# TPCC register map
Vendor: Texas Instruments
Registers are 32-bit, read-only, no defined reset value unless marked. A register's access mark holds for its fields unless they carry their own. Offsets are as the file gives them; [hi:lo] are bit positions; {n}, {i} and the like mark numbered series.

## TPCC (part 2 of 2)
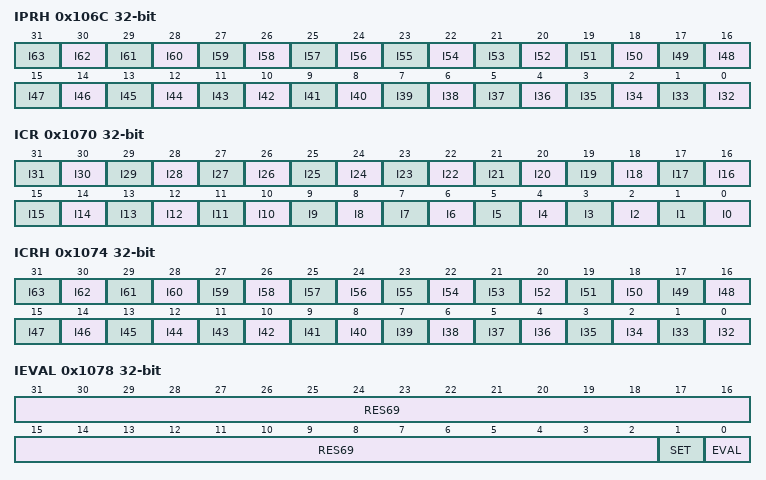
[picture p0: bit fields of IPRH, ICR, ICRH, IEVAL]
0x106C IPRH — Interrupt Pending Register (High Part): IPRH.In bit is set when a interrupt completion code with TCC of N is detected. IPRH.In bit is cleared via software by writing a '1' to ICRH.In bit.
  [n-32] I{n} (n=32..63) — Interrupt associated with TCC #{n}
0x1070 ICR wo — Interrupt Clear Register: CPU write of '1' to the ICR.In bit causes the IPR.In bit to be cleared. CPU write of '0' has no effect. All IPR.In bits must be cleared before additional interrupts will be asserted by CC.
  [n] I{n} (n=0..31) — Interrupt associated with TCC #{n}
0x1074 ICRH wo — Interrupt Clear Register (High Part): CPU write of '1' to the ICRH.In bit causes the IPRH.In bit to be cleared. CPU write of '0' has no effect. All IPRH.In bits must be cleared before additional interrupts will be asserted by CC.
  [n-32] I{n} (n=32..63) — Interrupt associated with TCC #{n}
0x1078 IEVAL access per field — Interrupt Eval Register
  [31:2] RES69 ro — RESERVE FIELD
  [1] SET wo — Interrupt Set: CPU write of '1' to the SETn bit causes the tpcc_intN output signal to be pulsed egardless of state of interrupts enable (IERn) and status (IPRn). CPU write of '0' has no effect.
  [0] EVAL wo — Interrupt Evaluate: CPU write of '1' to the EVALn bit causes the tpcc_intN output signal to be pulsed if any enabled interrupts (IERn) are still pending (IPRn). CPU write of '0' has no effect..
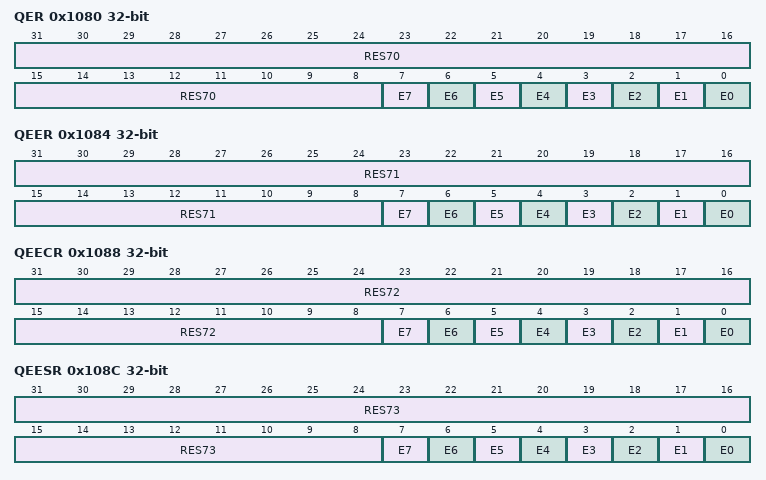
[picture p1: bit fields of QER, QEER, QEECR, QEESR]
0x1080 QER — QDMA Event Register: If QER.En bit is set then the corresponding QDMA channel is prioritized vs. other qdma events for submission to the TC. QER.En bit is set when a vbus write byte matches the address defined in the QCHMAPn register. QER.En bit is cleared when the corresponding event is prioritized and serviced. QER.En is also cleared when user writes a '1' to the QSECR.En bit. If the QER.En bit is already set and a new QDMA event is detected due to user write to QDMA trigger location and QEER register is set then the corresponding bit in the QDMA Event Missed Register is set.
  [31:8] RES70 — RESERVE FIELD
  [n] E{n} (n=0..7) — Event #{n}
0x1084 QEER — QDMA Event Enable Register: Enabled/disabled QDMA address comparator for QDMA Channel N. QEER.En is not directly writeable. QDMA channels can be enabled via writes to QEESR and can be disabled via writes to QEECR register. QEER.En = 1 The corresponding QDMA channel comparator is enabled and Events will be recognized and latched in QER.En. QEER.En = 0 The corresponding QDMA channel comparator is disabled. Events will not be recognized/latched in QER.En.
  [31:8] RES71 — RESERVE FIELD
  [n] E{n} (n=0..7) — Event #{n}
0x1088 QEECR access per field — QDMA Event Enable Clear Register: CPU write of '1' to the QEECR.En bit causes the QEER.En bit to be cleared. CPU write of '0' has no effect..
  [31:8] RES72 ro — RESERVE FIELD
  [n] E{n} wo (n=0..7) — Event #{n}
0x108C QEESR access per field — QDMA Event Enable Set Register: CPU write of '1' to the QEESR.En bit causes the QEESR.En bit to be set. CPU write of '0' has no effect..
  [31:8] RES73 ro — RESERVE FIELD
  [n] E{n} wo (n=0..7) — Event #{n}
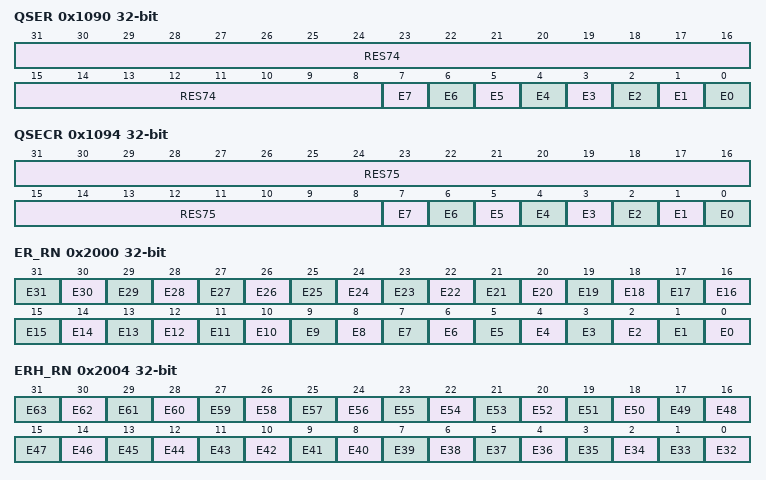
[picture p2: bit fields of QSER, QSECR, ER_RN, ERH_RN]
0x1090 QSER — QDMA Secondary Event Register: The QDMA secondary event register is used along with the QDMA Event Register (QER) to provide information on the state of a QDMA Event. En = 0 : Event is not currently in the Event Queue. En = 1 : Event is currently stored in Event Queue. Event arbiter will not prioritize additional events.
  [31:8] RES74 — RESERVE FIELD
  [n] E{n} (n=0..7) — Event #{n}
0x1094 QSECR access per field — QDMA Secondary Event Clear Register: The secondary event clear register is used to clear the status of the QSER and QER register (note that this is slightly different than the SER operation which does not clear the ER.En register). CPU write of '1' to the QSECR.En bit clears the QSER.En and QER.En register fields. CPU write of '0' has no effect..
  [31:8] RES75 ro — RESERVE FIELD
  [n] E{n} wo (n=0..7) — Event #{n}
0x2000 ER_RN — Event Register: If ER.En bit is set and the EER.En bit is also set then the corresponding DMA channel is prioritized vs. other pending DMA events for submission to the TC. ER.En bit is set when the input event #n transitions from inactive (low) to active (high) regardless of the state of EER.En bit. ER.En bit is cleared when the corresponding event is prioritized and serviced. If the ER.En bit is already set and a new inactive to active transition is detected on the input event #n input AND the corresponding bit in the EER register is set then the corresponding bit in the Event Missed Register is set. Event N can be cleared via sw by writing a '1' to the ECR pseudo-register.
  [n] E{n} (n=0..31) — Event #{n}
0x2004 ERH_RN — Event Register (High Part): If ERH.En bit is set and the EERH.En bit is also set then the corresponding DMA channel is prioritized vs. other pending DMA events for submission to the TC. ERH.En bit is set when the input event #n transitions from inactive (low) to active (high) regardless of the state of EERH.En bit. ER.En bit is cleared when the corresponding event is prioritized and serviced. If the ERH.En bit is already set and a new inactive to active transition is detected on the input event #n input AND the corresponding bit in the EERH register is set then the corresponding bit in the Event Missed Register is set. Event N can be cleared via sw by writing a '1' to the ECRH pseudo-register.
  [n-32] E{n} (n=32..63) — Event #{n}
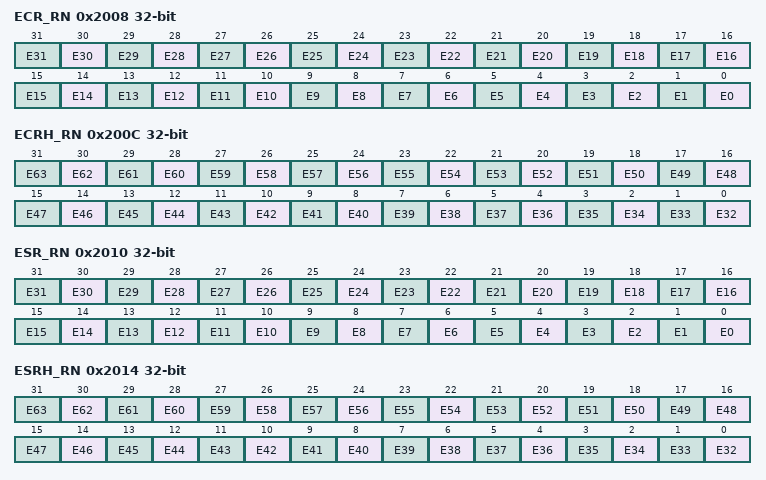
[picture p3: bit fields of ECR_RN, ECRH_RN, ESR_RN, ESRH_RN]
0x2008 ECR_RN wo — Event Clear Register: CPU write of '1' to the ECR.En bit causes the ER.En bit to be cleared. CPU write of '0' has no effect.
  [n] E{n} (n=0..31) — Event #{n}
0x200C ECRH_RN wo — Event Clear Register (High Part): CPU write of '1' to the ECRH.En bit causes the ERH.En bit to be cleared. CPU write of '0' has no effect.
  [n-32] E{n} (n=32..63) — Event #{n}
0x2010 ESR_RN wo — Event Set Register: CPU write of '1' to the ESR.En bit causes the ER.En bit to be set. CPU write of '0' has no effect.
  [n] E{n} (n=0..31) — Event #{n}
0x2014 ESRH_RN wo — Event Set Register (High Part) CPU write of '1' to the ESRH.En bit causes the ERH.En bit to be set. CPU write of '0' has no effect.
  [n-32] E{n} (n=32..63) — Event #{n}
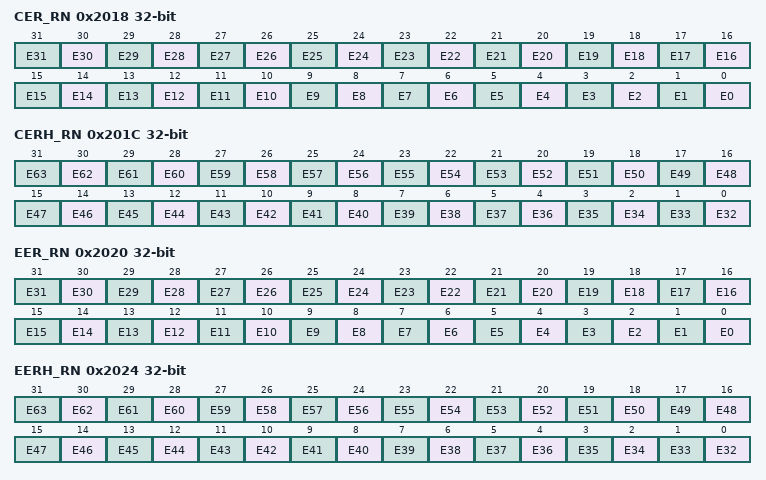
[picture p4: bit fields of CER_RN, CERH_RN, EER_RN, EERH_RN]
0x2018 CER_RN — Chained Event Register: If CER.En bit is set (regardless of state of EER.En) then the corresponding DMA channel is prioritized vs. other pending DMA events for submission to the TC. CER.En bit is set when a chaining completion code is returned from one of the 3PTCs via the completion interface or is generated internally via Early Completion path. CER.En bit is cleared when the corresponding event is prioritized and serviced. If the CER.En bit is already set and the corresponding chaining completion code is returned from the TC then the corresponding bit in the Event Missed Register is set. CER.En cannot be set or cleared via software.
  [n] E{n} (n=0..31) — Event #{n}
0x201C CERH_RN — Chained Event Register (High Part): If CERH.En bit is set (regardless of state of EERH.En) then the corresponding DMA channel is prioritized vs. other pending DMA events for submission to the TC. CERH.En bit is set when a chaining completion code is returned from one of the 3PTCs via the completion interface or is generated internally via Early Completion path. CERH.En bit is cleared when the corresponding event is prioritized and serviced. If the CERH.En bit is already set and the corresponding chaining completion code is returned from the TC then the corresponding bit in the Event Missed Register is set. CERH.En cannot be set or cleared via software.
  [n-32] E{n} (n=32..63) — Event #{n}
0x2020 EER_RN — Event Enable Register: Enables DMA transfers for ER.En pending events. ER.En is set based on externally asserted events (via tpcc_eventN_pi). This register has no effect on Chained Event Register (CER) or Event Set Register (ESR). Note that if a bit is set in ER.En while EER.En is disabled no action is taken. If EER.En is enabled at a later point (and ER.En has not been cleared via SW) then the event will be recognized as a valid 'TR Sync' EER.En is not directly writeable. Events can be enabled via writes to EESR and can be disabled via writes to EECR register. EER.En = 0: ER.En is not enabled to trigger DMA transfers. EER.En = 1: ER.En is enabled to trigger DMA transfers.
  [n] E{n} (n=0..31) — Event #{n}
0x2024 EERH_RN — Event Enable Register (High Part): Enables DMA transfers for ERH.En pending events. ERH.En is set based on externally asserted events (via tpcc_eventN_pi). This register has no effect on Chained Event Register (CERH) or Event Set Register (ESRH). Note that if a bit is set in ERH.En while EERH.En is disabled no action is taken. If EERH.En is enabled at a later point (and ERH.En has not been cleared via SW) then the event will be recognized as a valid 'TR Sync' EERH.En is not directly writeable. Events can be enabled via writes to EESRH and can be disabled via writes to EECRH register. EERH.En = 0: ER.En is not enabled to trigger DMA transfers. EERH.En = 1: ER.En is enabled to trigger DMA transfers.
  [n-32] E{n} (n=32..63) — Event #{n}
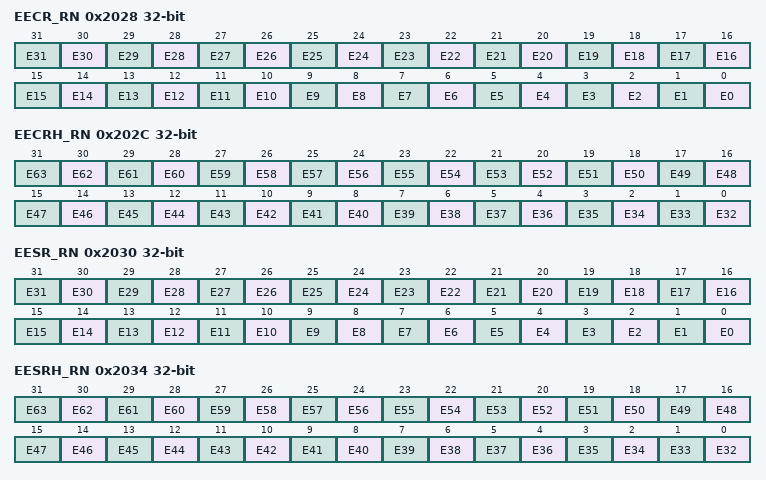
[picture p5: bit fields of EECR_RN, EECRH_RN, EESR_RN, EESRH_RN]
0x2028 EECR_RN wo — Event Enable Clear Register: CPU write of '1' to the EECR.En bit causes the EER.En bit to be cleared. CPU write of '0' has no effect..
  [n] E{n} (n=0..31) — Event #{n}
0x202C EECRH_RN wo — Event Enable Clear Register (High Part): CPU write of '1' to the EECRH.En bit causes the EERH.En bit to be cleared. CPU write of '0' has no effect..
  [n-32] E{n} (n=32..63) — Event #{n}
0x2030 EESR_RN wo — Event Enable Set Register: CPU write of '1' to the EESR.En bit causes the EER.En bit to be set. CPU write of '0' has no effect..
  [n] E{n} (n=0..31) — Event #{n}
0x2034 EESRH_RN wo — Event Enable Set Register (High Part): CPU write of '1' to the EESRH.En bit causes the EERH.En bit to be set. CPU write of '0' has no effect..
  [n-32] E{n} (n=32..63) — Event #{n}
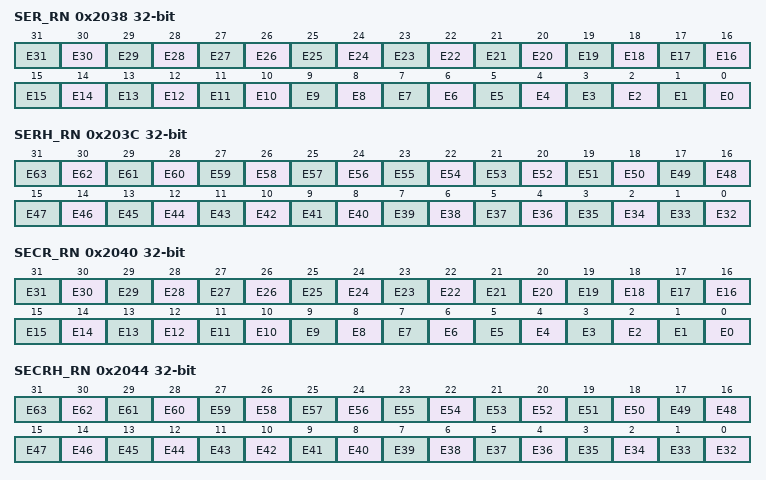
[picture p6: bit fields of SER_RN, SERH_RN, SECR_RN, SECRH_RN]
0x2038 SER_RN — Secondary Event Register: The secondary event register is used along with the Event Register (ER) to provide information on the state of an Event. En = 0 : Event is not currently in the Event Queue. En = 1 : Event is currently stored in Event Queue. Event arbiter will not prioritize additional events.
  [n] E{n} (n=0..31) — Event #{n}
0x203C SERH_RN — Secondary Event Register (High Part): The secondary event register is used along with the Event Register (ERH) to provide information on the state of an Event. En = 0 : Event is not currently in the Event Queue. En = 1 : Event is currently stored in Event Queue. Event arbiter will not prioritize additional events.
  [n-32] E{n} (n=32..63) — Event #{n}
0x2040 SECR_RN wo — Secondary Event Clear Register: The secondary event clear register is used to clear the status of the SER registers. CPU write of '1' to the SECR.En bit clears the SER register. CPU write of '0' has no effect.
  [n] E{n} (n=0..31) — Event #{n}
0x2044 SECRH_RN wo — Secondary Event Clear Register (High Part): The secondary event clear register is used to clear the status of the SERH registers. CPU write of '1' to the SECRH.En bit clears the SERH register. CPU write of '0' has no effect.
  [n-32] E{n} (n=32..63) — Event #{n}
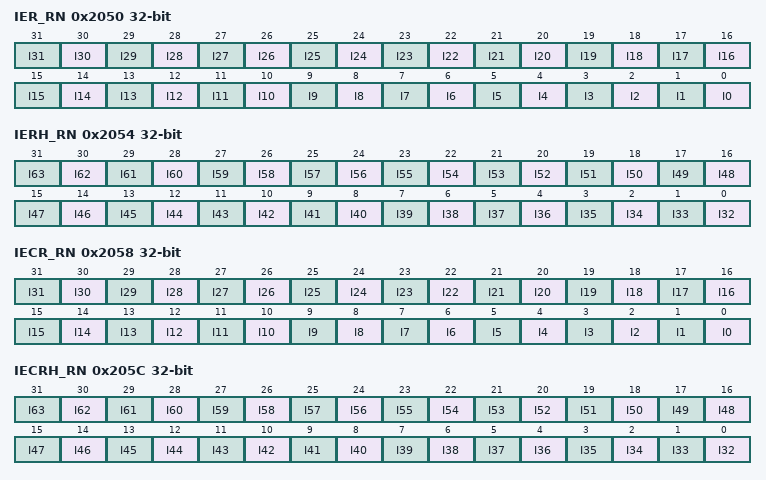
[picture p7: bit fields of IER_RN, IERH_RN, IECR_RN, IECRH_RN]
0x2050 IER_RN — Int Enable Register: IER.In is not directly writeable. Interrupts can be enabled via writes to IESR and can be disabled via writes to IECR register. IER.In = 0: IPR.In is NOT enabled for interrupts. IER.In = 1: IPR.In IS enabled for interrupts.
  [n] I{n} (n=0..31) — Interrupt associated with TCC #{n}
0x2054 IERH_RN — Int Enable Register (High Part): IERH.In is not directly writeable. Interrupts can be enabled via writes to IESRH and can be disabled via writes to IECRH register. IERH.In = 0: IPRH.In is NOT enabled for interrupts. IERH.In = 1: IPRH.In IS enabled for interrupts.
  [n-32] I{n} (n=32..63) — Interrupt associated with TCC #{n}
0x2058 IECR_RN wo — Int Enable Clear Register: CPU write of '1' to the IECR.In bit causes the IER.In bit to be cleared. CPU write of '0' has no effect..
  [n] I{n} (n=0..31) — Interrupt associated with TCC #{n}
0x205C IECRH_RN wo — Int Enable Clear Register (High Part): CPU write of '1' to the IECRH.In bit causes the IERH.In bit to be cleared. CPU write of '0' has no effect..
  [n-32] I{n} (n=32..63) — Interrupt associated with TCC #{n}
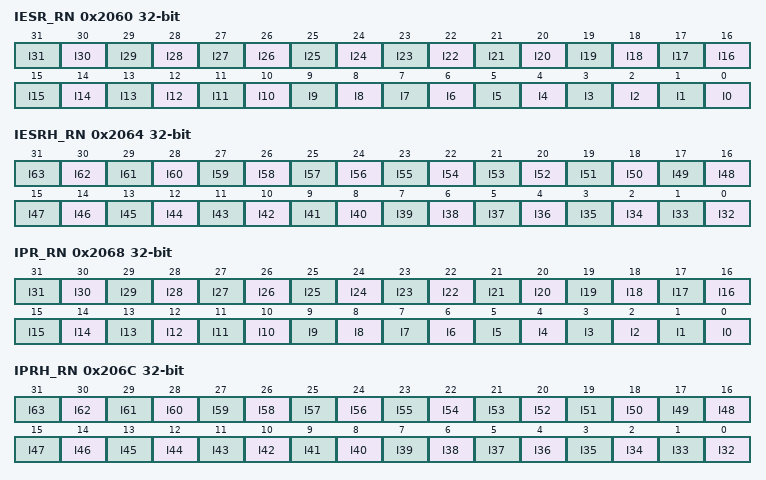
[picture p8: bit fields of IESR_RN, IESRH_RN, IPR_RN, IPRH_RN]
0x2060 IESR_RN wo — Int Enable Set Register: CPU write of '1' to the IESR.In bit causes the IESR.In bit to be set. CPU write of '0' has no effect..
  [n] I{n} (n=0..31) — Interrupt associated with TCC #{n}
0x2064 IESRH_RN wo — Int Enable Set Register (High Part): CPU write of '1' to the IESRH.In bit causes the IESRH.In bit to be set. CPU write of '0' has no effect..
  [n-32] I{n} (n=32..63) — Interrupt associated with TCC #{n}
0x2068 IPR_RN — Interrupt Pending Register: IPR.In bit is set when a interrupt completion code with TCC of N is detected. IPR.In bit is cleared via software by writing a '1' to ICR.In bit.
  [n] I{n} (n=0..31) — Interrupt associated with TCC #{n}
0x206C IPRH_RN — Interrupt Pending Register (High Part): IPRH.In bit is set when a interrupt completion code with TCC of N is detected. IPRH.In bit is cleared via software by writing a '1' to ICRH.In bit.
  [n-32] I{n} (n=32..63) — Interrupt associated with TCC #{n}
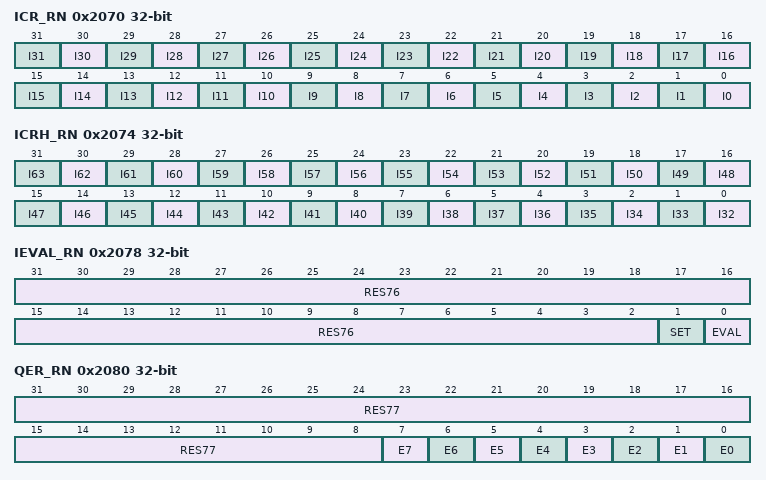
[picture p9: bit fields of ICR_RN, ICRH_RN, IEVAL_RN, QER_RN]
0x2070 ICR_RN wo — Interrupt Clear Register: CPU write of '1' to the ICR.In bit causes the IPR.In bit to be cleared. CPU write of '0' has no effect. All IPR.In bits must be cleared before additional interrupts will be asserted by CC.
  [n] I{n} (n=0..31) — Interrupt associated with TCC #{n}
0x2074 ICRH_RN wo — Interrupt Clear Register (High Part): CPU write of '1' to the ICRH.In bit causes the IPRH.In bit to be cleared. CPU write of '0' has no effect. All IPRH.In bits must be cleared before additional interrupts will be asserted by CC.
  [n-32] I{n} (n=32..63) — Interrupt associated with TCC #{n}
0x2078 IEVAL_RN access per field — Interrupt Eval Register
  [31:2] RES76 ro — RESERVE FIELD
  [1] SET wo — Interrupt Set: CPU write of '1' to the SETn bit causes the tpcc_intN output signal to be pulsed egardless of state of interrupts enable (IERn) and status (IPRn). CPU write of '0' has no effect.
  [0] EVAL wo — Interrupt Evaluate: CPU write of '1' to the EVALn bit causes the tpcc_intN output signal to be pulsed if any enabled interrupts (IERn) are still pending (IPRn). CPU write of '0' has no effect..
0x2080 QER_RN — QDMA Event Register: If QER.En bit is set then the corresponding QDMA channel is prioritized vs. other qdma events for submission to the TC. QER.En bit is set when a vbus write byte matches the address defined in the QCHMAPn register. QER.En bit is cleared when the corresponding event is prioritized and serviced. QER.En is also cleared when user writes a '1' to the QSECR.En bit. If the QER.En bit is already set and a new QDMA event is detected due to user write to QDMA trigger location and QEER register is set then the corresponding bit in the QDMA Event Missed Register is set.
  [31:8] RES77 — RESERVE FIELD
  [n] E{n} (n=0..7) — Event #{n}
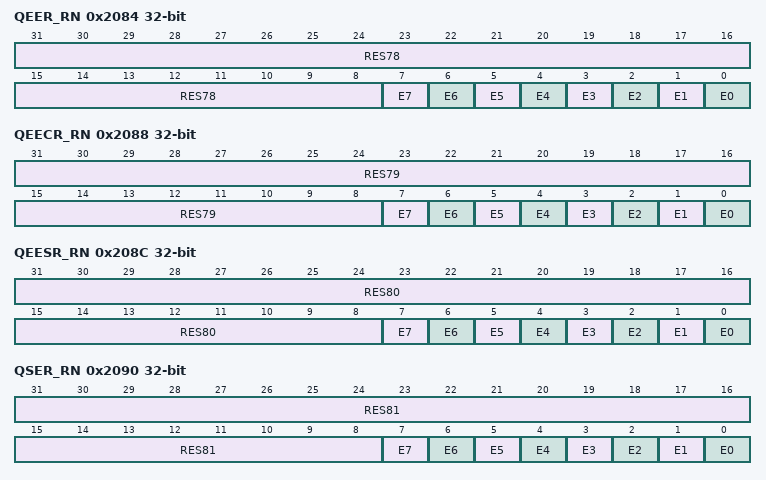
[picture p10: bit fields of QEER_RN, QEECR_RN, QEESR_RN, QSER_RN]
0x2084 QEER_RN — QDMA Event Enable Register: Enabled/disabled QDMA address comparator for QDMA Channel N. QEER.En is not directly writeable. QDMA channels can be enabled via writes to QEESR and can be disabled via writes to QEECR register. QEER.En = 1 The corresponding QDMA channel comparator is enabled and Events will be recognized and latched in QER.En. QEER.En = 0 The corresponding QDMA channel comparator is disabled. Events will not be recognized/latched in QER.En.
  [31:8] RES78 — RESERVE FIELD
  [n] E{n} (n=0..7) — Event #{n}
0x2088 QEECR_RN access per field — QDMA Event Enable Clear Register: CPU write of '1' to the QEECR.En bit causes the QEER.En bit to be cleared. CPU write of '0' has no effect..
  [31:8] RES79 ro — RESERVE FIELD
  [n] E{n} wo (n=0..7) — Event #{n}
0x208C QEESR_RN access per field — QDMA Event Enable Set Register: CPU write of '1' to the QEESR.En bit causes the QEESR.En bit to be set. CPU write of '0' has no effect..
  [31:8] RES80 ro — RESERVE FIELD
  [n] E{n} wo (n=0..7) — Event #{n}
0x2090 QSER_RN — QDMA Secondary Event Register: The QDMA secondary event register is used along with the QDMA Event Register (QER) to provide information on the state of a QDMA Event. En = 0 : Event is not currently in the Event Queue. En = 1 : Event is currently stored in Event Queue. Event arbiter will not prioritize additional events.
  [31:8] RES81 — RESERVE FIELD
  [n] E{n} (n=0..7) — Event #{n}
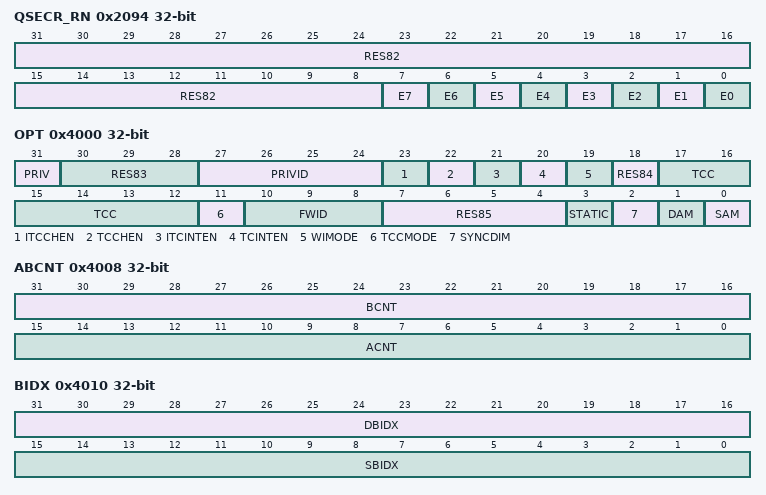
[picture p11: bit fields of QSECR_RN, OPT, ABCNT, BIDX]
0x2094 QSECR_RN access per field — QDMA Secondary Event Clear Register: The secondary event clear register is used to clear the status of the QSER and QER register (note that this is slightly different than the SER operation which does not clear the ER.En register). CPU write of '1' to the QSECR.En bit clears the QSER.En and QER.En register fields. CPU write of '0' has no effect..
  [31:8] RES82 ro — RESERVE FIELD
  [n] E{n} wo (n=0..7) — Event #{n}
0x4000 OPT access per field — Options Parameter
  [31] PRIV ro — Privilege level: privilege level (supervisor vs. user) for the host/cpu/dma that programmed this PaRAM Entry. Value is set with the vbus priv value when any part of the PaRAM Entry is written. Not writeable via vbus wdata bus. Is readable via VBus rdata bus. PRIV = 0 : User level privilege PRIV = 1 : Supervisor level privilege
  [30:28] RES83 ro — RESERVE FIELD
  [27:24] PRIVID ro — Privilege ID: Privilege ID for the external host/cpu/dma that programmed this PaRAM Entry. This value is set with the vbus privid value when any part of the PaRAM Entry is written. Not writeable via vbus wdata bus. Is readable via VBus rdata bus.
  [23] ITCCHEN rw — Intermediate transfer completion chaining enable: 0: Intermediate transfer complete chaining is disabled. 1: Intermediate transfer complete chaining is enabled.
  [22] TCCHEN rw — Transfer complete chaining enable: 0: Transfer complete chaining is disabled. 1: Transfer complete chaining is enabled.
  [21] ITCINTEN rw — Intermediate transfer completion interrupt enable: 0: Intermediate transfer complete interrupt is disabled. 1: Intermediate transfer complete interrupt is enabled (corresponding IER[TCC] bit must be set to 1 to generate interrupt)
  [20] TCINTEN rw — Transfer complete interrupt enable: 0: Transfer complete interrupt is disabled. 1: Transfer complete interrupt is enabled (corresponding IER[TCC] bit must be set to 1 to generate interrupt)
  [19] WIMODE rw — Backward compatibility mode: 0: Normal operation 1 : WI Backwards Compatibility mode forces BCNT to be adjusted by '1' upon TR submission (0 means 1 1 means 2 ... ) and forces ACNT to be treated as a word-count (left shifted by 2 by hardware to create byte cnt for TR submission)
  [18] RES84 ro — RESERVE FIELD
  [17:12] TCC rw — Transfer Complete Code: The 6-bit code is used to set the relevant bit in CER (bit CER[TCC]) for chaining or in IER (bit IER[TCC]) for interrupts.
  [11] TCCMODE rw — Transfer complete code mode: Indicates the point at which a transfer is considered completed. Applies to both chaining and interrupt. 0: Normal Completion A transfer is considered completed after the transfer parameters are returned to the CC from the TC (which was returned from the peripheral). 1: Early Completion A transfer is considered completed after the CC submits a TR to the TC. CC generates completion code internally .
  [10:8] FWID rw — FIFO width: Applies if either SAM or DAM is set to FIFO mode. Pass-thru to TC.
  [7:4] RES85 ro — RESERVE FIELD
  [3] STATIC rw — Static Entry: 0: Entry is updated as normal 1: Entry is static Count and Address updates are not updated after TRP is submitted. Linking is not performed.
  [2] SYNCDIM rw — Transfer Synchronization Dimension: 0: A-Sync Each event triggers the transfer of ACNT elements. 1: AB-Sync Each event triggers the transfer of BCNT arrays of ACNT elements
  [1] DAM rw — Destination Address Mode: Destination Address Mode within an array. Pass-thru to TC. 0: INCR Dst addressing within an array increments. Dst is not a FIFO. 1: FIFO Dst addressing within an array wraps around upon reaching FIFO width.
  [0] SAM rw — Source Address Mode: Source Address Mode within an array. Pass-thru to TC. 0: INCR Src addressing within an array increments. Source is not a FIFO. 1: FIFO Src addressing within an array wraps around upon reaching FIFO width.
0x4004 SRC rw — Source Address
  [31:0] SRC — Source Address: The 32-bit source address parameters specify the starting byte address of the source . If SAM is set to FIFO mode then the user should program the Source address to be aligned to the value specified by the OPT.FWID field. No errors are recognized here but TC will assert error if this is not true.
0x4008 ABCNT rw — A and B byte count
  [31:16] BCNT — BCNT : Count for 2nd Dimension: BCNT is a 16-bit unsigned value that specifies the number of arrays of length ACNT. For normal operation valid values for BCNT can be anywhere between 1 and 65535. Therefore the maximum number of arrays in a frame is 65535 (64K-1 arrays). BCNT=1 means 1 array in the frame and BCNT=0 means 0 arrays in the frame. In normal mode a BCNT of '0' is considered as either a Null or Dummy transfer. A Dummy or Null transfer will generate a Completion code depending on the settings of the completion bit fields of the OPT field. If the OPT.WIMODE bit is set then the programmed BCNT value will be incremented by '1' before submission to TC. I.e. 0 means 1 1 means 2 2 means 3 ...
  [15:0] ACNT — ACNT : number of bytes in 1st dimension: ACNT represents the number of bytes within the first dimension of a transfer. ACNT is a 16-bit unsigned value with valid values between 0 and 65535. Therefore the maximum number of bytes in an array is 65535 bytes (64K-1 bytes). ACNT must be greater than or equal to '1' for a TR to be submitted to TC. An ACNT of '0' is considered as either a null or dummy transfer. A Dummy or Null transfer will generate a Completion code depending on the settings of the completion bit fields of the OPT field. If the OPT.WIMODE bit is set then the ACNT field represents a word count. The CC must internally multiply by 4 to translate the word count to a byte count prior to submission to the TC. The 2 MSBs of the 16-bit ACNT are reserved and should always be written as 'b00 by the user. If user writes a value other than 0 it will still be treated as 0 since the multiply-by-4 operation (to translate between a word count and a byte count) will drop the 2 msbits. For dummy and null transfer definition the ACNT definition will disregard the 2 msbits. I.e. a programmed ACNT value of 0x8000 in WI-mode will be treated as 0 byte transfer resulting in null or dummy operation dependent on the state of BCNT and CCNT.
0x400C DST rw — Destination Address
  [31:0] DST — Destination Address: The 32-bit destination address parameters specify the starting byte address of the destination. If DAM is set to FIFO mode then the user should program the Destination address to be aligned to the value specified by the OPT.FWID field. No errors are recognized here but TC will assert error if this is not true.
0x4010 BIDX rw — Register description is not available
  [31:16] DBIDX — Destination 2nd Dimension Index: DBIDX is a 16-bit signed value (2's complement) used for destination address modification in between each array in the 2nd dimension. It is a signed value between -32768 and 32767. It provides a byte address offset from the beginning of the destination array to the beginning of the next destination array within the current frame. It applies to both A-Sync and AB-Sync transfers.
  [15:0] SBIDX — Source 2nd Dimension Index: SBIDX is a 16-bit signed value (2's complement) used for source address modification in between each array in the 2nd dimension. It is a signed value between -32768 and 32767. It provides a byte address offset from the beginning of the source array to the beginning of the next source array. It applies to both A-sync and AB-sync transfers.
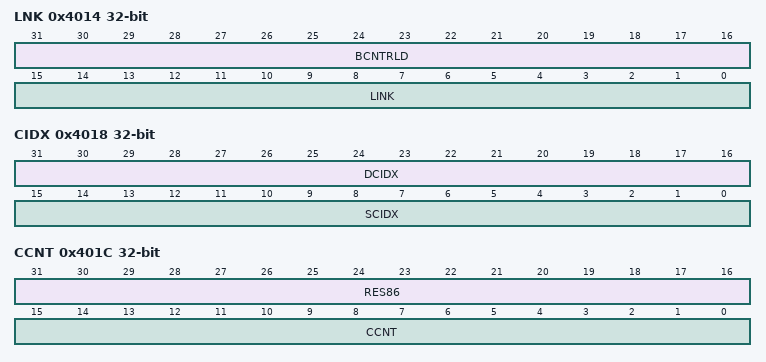
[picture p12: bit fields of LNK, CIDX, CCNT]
0x4014 LNK rw — Link and Reload parameters
  [31:16] BCNTRLD — BCNT Reload: BCNTRLD is a 16-bit unsigned value used to reload the BCNT field once the last array in the 2nd dimension is transferred. This field is only used for A-Sync'ed transfers. In this case the CC decrements the BCNT value by one on each TR submission. When BCNT (conceptually) reaches zero then the CC decrements CCNT and uses the BCNTRLD value to reinitialize the BCNT value. For AB-synchronized transfers the CC submits the BCNT in the TR and therefore the TC is responsible to keep track of BCNT not thus BCNTRLD is a don't care field.
  [15:0] LINK — Link Address: The CC provides a mechanism to reload the current PaRAM Entry upon its natural termination (i.e. after count fields are decremented to '0') with a new PaRAM Entry. This is called 'linking'. The 16-bit parameter LINK specifies the byte address offset in the PaRAM from which the CC loads/reloads the next PaRAM entry in the link. The CC should disregard the value in the upper 2 bits of the LINK field as well as the lower 5-bits of the LINK field. The upper two bits are ignored such that the user can program either the 'literal' byte address of the LINK parameter or the 'PaRAM base-relative' address of the link field. Therefore if the user uses the literal address with a range from 0x4000 to 0x7FFF it will be treated as a PaRAM-base-relative value of 0x0000 to 0x3FFF. The lower-5 bits are ignored and treated as 'b00000 thereby guaranteeing that all Link pointers point to a 32-byte aligned PaRAM entry. In the latter case (5-lsbs) behavior is undefined for the user (i.e. don't have to test it). In the former case (2 msbs) user should be able to take advantage of this feature (i.e. do have to test it). If a Link Update is requested to a PaRAM address that is beyond the actual range of implemented PaRAM then the Link will be treated as a Null Linkand all 0s plus 0xFFFF will be written to the current entry location. A LINK value of 0xFFFF is referred to as a NULL link which should cause the CC to write 0x0 to all entries of the current PaRAM Entry except for the LINK field which is set to 0xFFFF. The Priv/Privid/Secure state is overwritten to 0x0 when linking. MSBs and LSBS should not be masked when comparing against the 0xFFFF value. I.e. a value of 0x3FFE is a non-NULL PaRAM link field.
0x4018 CIDX rw — Register description is not available
  [31:16] DCIDX — Destination Frame Index: DCIDX is a 16-bit signed value (2's complement) used for destination address modification for the 3rd dimension. It is a signed value between -32768 and 32767. It provides a byte address offset from the beginning of the current array (pointed to by DST address) to the beginning of the first destination array in the next frame. It applies to both A-sync and AB-sync transfers. Note that when DCIDX is applied the current array in an A-sync transfer is the last array in the frame while the current array in a ABsync transfer is the first array in the frame.
  [15:0] SCIDX — Source Frame Index: SCIDX is a 16-bit signed value (2's complement) used for source address modification for the 3rd dimension. It is a signed value between -32768 and 32767. It provides a byte address offset from the beginning of the current array (pointed to by SRC address) to the beginning of the first source array in the next frame. It applies to both A-sync and AB-sync transfers. Note that when SCIDX is applied the current array in an A-sync transfer is the last array in the frame while the current array in a AB-sync transfer is the first array in the frame.
0x401C CCNT access per field — C byte count
  [31:16] RES86 ro — RESERVE FIELD
  [15:0] CCNT rw — CCNT : Count for 3rd Dimension: CCNT is a 16-bit unsigned value that specifies the number of frames in a block. Valid values for CCNT can be anywhere between 1 and 65535. Therefore the maximum number of frames in a block is 65535 (64K-1 frames). CCNT of '1' means '1' frame in the block and CCNT of '0' means '0' frames in the block. A CCNT value of '0' is considered as either a null or dummy transfer. A Dummy or Null transfer will generate a Completion code depending on the settings of the completion bit fields of the OPT field. WIMODE has no affect on CCNT operation.
